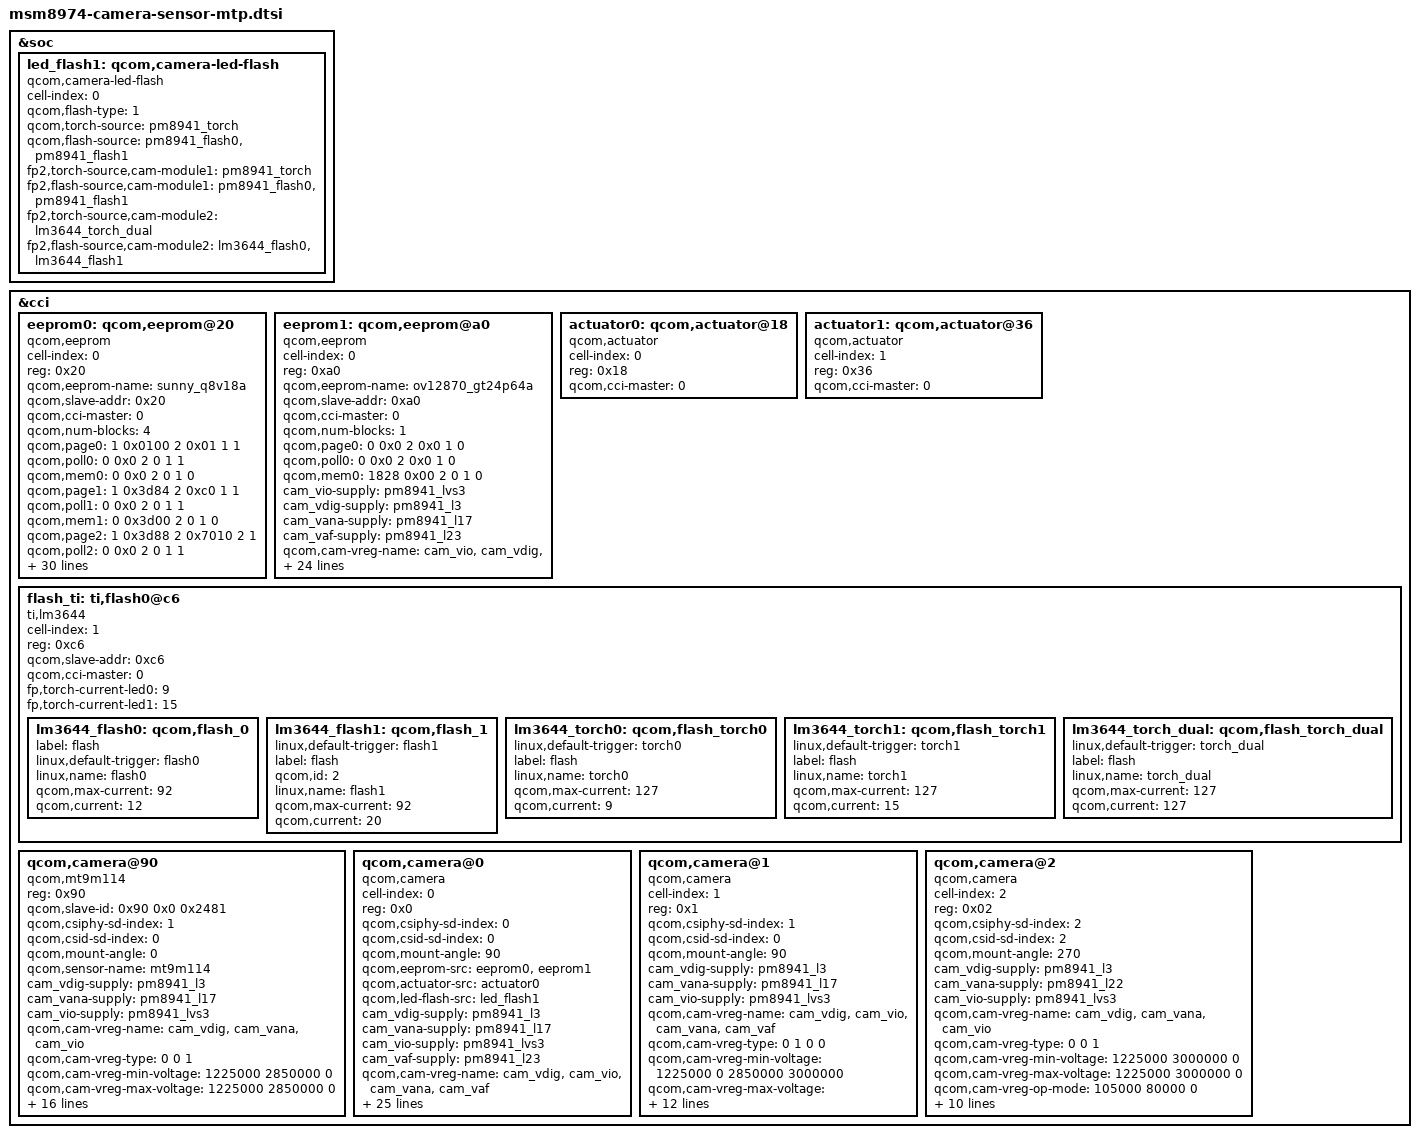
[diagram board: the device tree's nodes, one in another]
/*
 * Copyright (c) 2012-2014, The Linux Foundation. All rights reserved.
 *
 * This program is free software; you can redistribute it and/or modify
 * it under the terms of the GNU General Public License version 2 and
 * only version 2 as published by the Free Software Foundation.
 *
 * This program is distributed in the hope that it will be useful,
 * but WITHOUT ANY WARRANTY; without even the implied warranty of
 * MERCHANTABILITY or FITNESS FOR A PARTICULAR PURPOSE.  See the
 * GNU General Public License for more details.
 */

&soc {
    led_flash1: qcom,camera-led-flash {
        cell-index = <0>;
        compatible = "qcom,camera-led-flash";
        qcom,flash-type = <1>;
        qcom,torch-source = <&pm8941_torch>;
        qcom,flash-source = <&pm8941_flash0 &pm8941_flash1>;
        fp2,torch-source,cam-module1 = <&pm8941_torch>;
        fp2,flash-source,cam-module1 = <&pm8941_flash0 &pm8941_flash1>;
        fp2,torch-source,cam-module2 = <&lm3644_torch_dual>;
        fp2,flash-source,cam-module2 = <&lm3644_flash0 &lm3644_flash1>;
    };
};

&cci {
eeprom0: qcom,eeprom@20 {
             cell-index = <0>;
             reg = <0x20>;
             qcom,eeprom-name = "sunny_q8v18a";
             compatible = "qcom,eeprom";
             qcom,slave-addr = <0x20>;
             qcom,cci-master = <0>;
             qcom,num-blocks = <4>;
             qcom,page0 = <1 0x0100 2 0x01 1 1>;
             qcom,poll0 = <0 0x0 2 0 1 1>;
             qcom,mem0 = <0 0x0 2 0 1 0>;
             qcom,page1 = <1 0x3d84 2 0xc0 1 1>;
             qcom,poll1 = <0 0x0 2 0 1 1>;
             qcom,mem1 = <0 0x3d00 2 0 1 0>;
             qcom,page2 = <1 0x3d88 2 0x7010 2 1>;
             qcom,poll2 = <0 0x0 2 0 1 1>;
             qcom,mem2 = <0 0x3d00 2 0 1 0>;
             qcom,page3 = <1 0x3d8A 2 0x70F4 2 1>;
             qcom,pageen3 = <1 0x3d81 2 0x01 1 10>;
             qcom,poll3 = <0 0x0 2 0 1 1>;
             qcom,mem3 = <228 0x7010 2 0 1 1>;

             cam_vdig-supply = <&pm8941_l3>;
             cam_vana-supply = <&pm8941_l17>;
             cam_vio-supply = <&pm8941_lvs3>;
             qcom,cam-vreg-name = "cam_vdig","cam_vana", "cam_vio";
             qcom,cam-vreg-type = <0 0 1>;
             qcom,cam-vreg-min-voltage = <1225000 2850000 0>;
             qcom,cam-vreg-max-voltage = <1225000 2850000 0>;
             qcom,cam-vreg-op-mode = <105000 80000 0>;
             qcom,gpio-no-mux = <0>;
             gpios = <&msmgpio 15 0>,
                   <&msmgpio 90 0>,
                   <&msmgpio 89 0>;
             qcom,gpio-reset = <1>;
             qcom,gpio-standby = <2>;
             qcom,gpio-req-tbl-num = <0 1 2>;
             qcom,gpio-req-tbl-flags = <1 0 0>;
             qcom,gpio-req-tbl-label = "CAMIF_MCLK0",
                 "CAM_RESET0",
                 "CAM_STANDBY0";
             qcom,cam-power-seq-type = "sensor_vreg","sensor_vreg",
                 "sensor_vreg", "sensor_clk",
                 "sensor_gpio", "sensor_gpio";
             qcom,cam-power-seq-val = "cam_vdig","cam_vana",
                 "cam_vio", "sensor_cam_mclk",
                 "sensor_gpio_reset",
                 "sensor_gpio_standby";
             qcom,cam-power-seq-cfg-val = <1 1 1 24000000 1 1>;
             qcom,cam-power-seq-delay = <1 1 1 5 5 10>;
         };

eeprom1: qcom,eeprom@a0 {
             cell-index = <0>;
             reg = <0xa0>;
             qcom,eeprom-name = "ov12870_gt24p64a";
             compatible = "qcom,eeprom";
             qcom,slave-addr = <0xa0>;
             qcom,cci-master = <0>;
             qcom,num-blocks = <1>;

             /* valid_size, addr, addr_t, data, data_t, delay */
             qcom,page0 = <0 0x0 2 0x0 1 0>;
             qcom,poll0 = <0 0x0 2 0x0 1 0>;
             qcom,mem0 = <1828 0x00 2 0 1 0>;

             cam_vio-supply = <&pm8941_lvs3>;
             cam_vdig-supply = <&pm8941_l3>;
             cam_vana-supply = <&pm8941_l17>;
             cam_vaf-supply = <&pm8941_l23>;
             qcom,cam-vreg-name = "cam_vio", "cam_vdig", "cam_vana",
                                "cam_vaf";
             qcom,cam-vreg-type = <1 0 0 0>;
             qcom,cam-vreg-min-voltage = <0 1225000 2850000 3000000>;
             qcom,cam-vreg-max-voltage = <0 1225000 2850000 3000000>;
             qcom,cam-vreg-op-mode = <0 105000 80000 100000>;

             qcom,gpio-no-mux = <0>;
             gpios = <&msmgpio 15 0>,
                   <&msmgpio 90 0>,
                   <&msmgpio 89 0>;
             qcom,gpio-reset = <1>;
             qcom,gpio-standby = <2>;
             qcom,gpio-req-tbl-num = <0 1 2>;
             qcom,gpio-req-tbl-flags = <1 0 0>;
             qcom,gpio-req-tbl-label = "CAMIF_MCLK0",
                 "CAM_RESET0",
                 "CAM_STANDBY0";
             qcom,cam-power-seq-type = "sensor_vreg","sensor_vreg",
                 "sensor_vreg", "sensor_vreg", "sensor_clk",
                 "sensor_gpio", "sensor_gpio";
             qcom,cam-power-seq-val = "cam_vio","cam_vana",
                 "cam_vdig", "cam_vaf", "sensor_cam_mclk",
                 "sensor_gpio_reset",
                 "sensor_gpio_standby";
             qcom,cam-power-seq-cfg-val = <1 1 1 1 24000000 1 1>;
             qcom,cam-power-seq-delay = <1 1 1 5 5 5 10>;
         };

    actuator0: qcom,actuator@18 {
        cell-index = <0>;
        reg = <0x18>;
        compatible = "qcom,actuator";
        qcom,cci-master = <0>;
    };

    actuator1: qcom,actuator@36 {
        cell-index = <1>;
        reg = <0x36>;
        compatible = "qcom,actuator";
        qcom,cci-master = <0>;
    };

    flash_ti: ti,flash0@c6 {
        cell-index = <1>;
        reg = <0xc6>;
        qcom,slave-addr= <0xc6>;
        compatible = "ti,lm3644";
        qcom,cci-master = <0>;
        fp,torch-current-led0 = <9>;
        fp,torch-current-led1 = <15>;

        lm3644_flash0: qcom,flash_0 {
          label = "flash";
          linux,default-trigger =
            "flash0";
          linux,name = "flash0";
          qcom,max-current = <92>;
          qcom,current = <12>;
        };

        lm3644_flash1: qcom,flash_1 {
          linux,default-trigger =
            "flash1";
          label = "flash";
          qcom,id = <2>;
          linux,name = "flash1";
          qcom,max-current = <92>;
          qcom,current = <20>;
        };

        lm3644_torch0: qcom,flash_torch0 {
          linux,default-trigger =
            "torch0";
          label = "flash";
          linux,name = "torch0";
          qcom,max-current = <127>;
          qcom,current = <9>;
        };

        lm3644_torch1: qcom,flash_torch1 {
          linux,default-trigger =
            "torch1";
          label = "flash";
          linux,name = "torch1";
          qcom,max-current = <127>;
          qcom,current = <15>;
        };

        lm3644_torch_dual: qcom,flash_torch_dual {
          linux,default-trigger = "torch_dual";
          label = "flash";
          linux,name = "torch_dual";
          /*
           * Settings for current are ignored by this trigger but need to be
           * set for framework. Use fp,torch-current-led{0,1} above.
           */
          qcom,max-current = <127>;
          qcom,current = <127>;
        };
    };

    qcom,camera@90 {
        compatible = "qcom,mt9m114";
        reg = <0x90>;
        qcom,slave-id = <0x90 0x0 0x2481>;
        qcom,csiphy-sd-index = <1>;
        qcom,csid-sd-index = <0>;
        qcom,mount-angle = <0>;
        qcom,sensor-name = "mt9m114";
        cam_vdig-supply = <&pm8941_l3>;
        cam_vana-supply = <&pm8941_l17>;
        cam_vio-supply = <&pm8941_lvs3>;
        qcom,cam-vreg-name = "cam_vdig", "cam_vana", "cam_vio";
        qcom,cam-vreg-type = <0 0 1>;
        qcom,cam-vreg-min-voltage = <1225000 2850000 0>;
        qcom,cam-vreg-max-voltage = <1225000 2850000 0>;
        qcom,cam-vreg-op-mode = <105000 80000 0>;
        qcom,gpio-no-mux = <0>;
        gpios = <&msmgpio 16 0>,
            <&msmgpio 92 0>;
        qcom,gpio-reset = <1>;
        qcom,gpio-req-tbl-num = <0 1>;
        qcom,gpio-req-tbl-flags = <1 0>;
        qcom,gpio-req-tbl-label = "CAMIF_MCLK",
                      "CAM_RESET1";
        qcom,gpio-set-tbl-num = <1 1>;
        qcom,gpio-set-tbl-flags = <0 2>;
        qcom,gpio-set-tbl-delay = <1000 4000>;
        qcom,csi-lane-assign = <0x4320>;
        qcom,csi-lane-mask = <0x3>;
        qcom,sensor-position = <1>;
        qcom,sensor-mode = <1>;
        qcom,cci-master = <0>;
    };

    qcom,camera@0 {
        cell-index = <0>;
        compatible = "qcom,camera";
        reg = <0x0>;
        qcom,csiphy-sd-index = <0>;
        qcom,csid-sd-index = <0>;
        qcom,mount-angle = <90>;
        qcom,eeprom-src = <&eeprom0 &eeprom1>;
        qcom,actuator-src = <&actuator0>;
        qcom,led-flash-src = <&led_flash1>;
        cam_vdig-supply = <&pm8941_l3>;
        cam_vana-supply = <&pm8941_l17>;
        cam_vio-supply = <&pm8941_lvs3>;
        cam_vaf-supply = <&pm8941_l23>;
        qcom,cam-vreg-name = "cam_vdig", "cam_vio", "cam_vana",
                     "cam_vaf";
        qcom,cam-vreg-type = <0 1 0 0>;

        qcom,cam-vreg-min-voltage = <1225000 0 2850000 3000000>;
        qcom,cam-vreg-max-voltage = <1225000 0 2850000 3000000>;

        fp,cam-vreg-min-voltage,cam_module_1 = <1225000 0 2850000 3000000>;
        fp,cam-vreg-max-voltage,cam_module_1 = <1225000 0 2850000 3000000>;

        fp,cam-vreg-max-voltage,cam_module_2 = <1225000 0 3000000 3000000>;
        fp,cam-vreg-min-voltage,cam_module_2 = <1225000 0 3000000 3000000>;

        qcom,cam-vreg-op-mode = <105000 0 80000 100000>;
        qcom,gpio-no-mux = <0>;
        gpios = <&msmgpio 15 0>,
            <&msmgpio 90 0>,
            <&msmgpio 89 0>;
        qcom,gpio-reset = <1>;
        qcom,gpio-standby = <2>;
        qcom,gpio-req-tbl-num = <0 1 2>;
        qcom,gpio-req-tbl-flags = <1 0 0>;
        qcom,gpio-req-tbl-label = "CAMIF_MCLK0",
                      "CAM_RESET0",
                      "CAM_STANDBY0";
        qcom,sensor-position = <0>;
        qcom,sensor-mode = <0>;
        qcom,cci-master = <0>;
        status = "ok";
    };

    qcom,camera@1 {
        cell-index = <1>;
        compatible = "qcom,camera";
        reg = <0x1>;
        qcom,csiphy-sd-index = <1>;
        qcom,csid-sd-index = <0>;
        qcom,mount-angle = <90>;
        cam_vdig-supply = <&pm8941_l3>;
        cam_vana-supply = <&pm8941_l17>;
        cam_vio-supply = <&pm8941_lvs3>;
        qcom,cam-vreg-name = "cam_vdig", "cam_vio", "cam_vana",
                     "cam_vaf";
        qcom,cam-vreg-type = <0 1 0 0>;
        qcom,cam-vreg-min-voltage = <1225000 0 2850000 3000000>;
        qcom,cam-vreg-max-voltage = <1225000 0 2850000 3000000>;
        qcom,cam-vreg-op-mode = <105000 0 80000 100000>;
        gpios = <&msmgpio 16 0>,
            <&msmgpio 92 0>,
            <&msmgpio 91 0>;
        qcom,gpio-reset = <1>;
        qcom,gpio-standby = <2>;
        qcom,gpio-req-tbl-num = <0 1 2>;
        qcom,gpio-req-tbl-flags = <1 0 0>;
        qcom,gpio-req-tbl-label = "CAMIF_MCLK1",
                      "CAM_RESET1",
                      "CAM_STANDBY1";
        qcom,sensor-position = <0>;
        qcom,sensor-mode = <0>;
        qcom,cci-master = <0>;
        status = "ok";
    };
        qcom,camera@2 {
                cell-index = <2>;
                compatible = "qcom,camera";
                reg = <0x02>;
                qcom,csiphy-sd-index = <2>;
                qcom,csid-sd-index = <2>;
                qcom,mount-angle = <270>;
                cam_vdig-supply = <&pm8941_l3>;
                cam_vana-supply = <&pm8941_l22>;
                cam_vio-supply = <&pm8941_lvs3>;
                qcom,cam-vreg-name = "cam_vdig", "cam_vana", "cam_vio";
                qcom,cam-vreg-type = <0 0 1>;
                qcom,cam-vreg-min-voltage = <1225000 3000000 0>;
                qcom,cam-vreg-max-voltage = <1225000 3000000 0>;
                qcom,cam-vreg-op-mode = <105000 80000 0>;
                qcom,gpio-no-mux = <0>;
                gpios = <&msmgpio 17 0>,
                        <&msmgpio 18 0>;
                #qcom,gpio-reset = <1>;
                qcom,gpio-vdig = <1>;
                qcom,gpio-req-tbl-num = <0 1>;
                qcom,gpio-req-tbl-flags = <1 0>;
                qcom,gpio-req-tbl-label = "CAMIF_MCLK2",
                                          "CAM_VDIG";
                qcom,sensor-position = <1>;
                qcom,sensor-mode = <1>;
                qcom,cci-master = <1>;
        };

};
